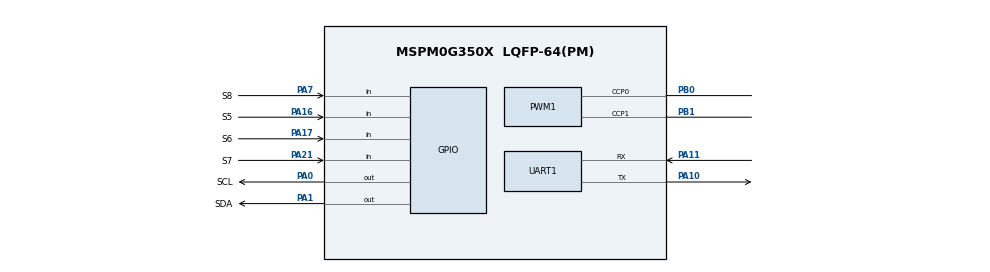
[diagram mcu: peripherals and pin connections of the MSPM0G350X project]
/**
 *
 * @cliArgs --device "MSPM0G350X" --part "Default" --package "LQFP-64(PM)" --product "mspm0_sdk@2.10.00.04"
 * @versions {"tool":"1.28.0+4712"}
 */

/**
 * Import the modules used in this configuration.
 */
const GPIO    = scripting.addModule("/ti/driverlib/GPIO", {}, false);
const GPIO1   = GPIO.addInstance();
const GPIO2   = GPIO.addInstance();
const GPIO3   = GPIO.addInstance();
const GPIO4   = GPIO.addInstance();
const GPIO5   = GPIO.addInstance();
const GPIO6   = GPIO.addInstance();
const GPIO7   = GPIO.addInstance();
const GPIO8   = GPIO.addInstance();
const GPIO9   = GPIO.addInstance();
const GPIO10  = GPIO.addInstance();
const PWM     = scripting.addModule("/ti/driverlib/PWM", {}, false);
const PWM1    = PWM.addInstance();
const SYSCTL  = scripting.addModule("/ti/driverlib/SYSCTL");
const SYSTICK = scripting.addModule("/ti/driverlib/SYSTICK");
const TIMER   = scripting.addModule("/ti/driverlib/TIMER", {}, false);
const TIMER1  = TIMER.addInstance();
const UART    = scripting.addModule("/ti/driverlib/UART", {}, false);
const UART1   = UART.addInstance();

/**
 * Write custom configuration values to the imported modules.
 */
const gate7  = system.clockTree["MFCLKGATE"];
gate7.enable = true;

GPIO1.port                               = "PORTB";
GPIO1.$name                              = "LED";
GPIO1.associatedPins[0].$name            = "PIN_0";
GPIO1.associatedPins[0].internalResistor = "PULL_DOWN";
GPIO1.associatedPins[0].assignedPin      = "22";

const Board = scripting.addModule("/ti/driverlib/Board", {}, false);

GPIO2.$name                              = "KEY";
GPIO2.port                               = "PORTB";
GPIO2.associatedPins[0].direction        = "INPUT";
GPIO2.associatedPins[0].internalResistor = "PULL_UP";
GPIO2.associatedPins[0].polarity         = "RISE";
GPIO2.associatedPins[0].$name            = "PIN_21";
GPIO2.associatedPins[0].assignedPin      = "21";

GPIO3.port                                = "PORTA";
GPIO3.$name                               = "ENCODERA";
GPIO3.associatedPins.create(2);
GPIO3.associatedPins[0].direction         = "INPUT";
GPIO3.associatedPins[0].interruptEn       = true;
GPIO3.associatedPins[0].polarity          = "RISE";
GPIO3.associatedPins[0].interruptPriority = "0";
GPIO3.associatedPins[0].$name             = "E1A";
GPIO3.associatedPins[0].assignedPin       = "8";
GPIO3.associatedPins[1].direction         = "INPUT";
GPIO3.associatedPins[1].interruptEn       = true;
GPIO3.associatedPins[1].polarity          = "RISE";
GPIO3.associatedPins[1].interruptPriority = "0";
GPIO3.associatedPins[1].$name             = "E1B";
GPIO3.associatedPins[1].assignedPin       = "9";

GPIO4.$name                         = "AIN1";
GPIO4.port                          = "PORTA";
GPIO4.associatedPins[0].$name       = "PIN_12";
GPIO4.associatedPins[0].assignedPin = "12";

GPIO5.$name                         = "AIN2";
GPIO5.port                          = "PORTA";
GPIO5.associatedPins[0].$name       = "PIN_13";
GPIO5.associatedPins[0].assignedPin = "13";

GPIO6.$name                         = "BIN1";
GPIO6.port                          = "PORTA";
GPIO6.associatedPins[0].$name       = "Pin_Bin1";
GPIO6.associatedPins[0].assignedPin = "14";

GPIO7.$name                         = "BIN2";
GPIO7.port                          = "PORTA";
GPIO7.associatedPins[0].$name       = "Pin_Bin2";
GPIO7.associatedPins[0].assignedPin = "15";

GPIO8.$name                               = "ENCODERB";
GPIO8.port                                = "PORTB";
GPIO8.associatedPins.create(2);
GPIO8.associatedPins[0].$name             = "E2A";
GPIO8.associatedPins[0].direction         = "INPUT";
GPIO8.associatedPins[0].interruptEn       = true;
GPIO8.associatedPins[0].polarity          = "RISE";
GPIO8.associatedPins[0].interruptPriority = "0";
GPIO8.associatedPins[0].assignedPin       = "14";
GPIO8.associatedPins[1].$name             = "E2B";
GPIO8.associatedPins[1].direction         = "INPUT";
GPIO8.associatedPins[1].interruptEn       = true;
GPIO8.associatedPins[1].polarity          = "RISE";
GPIO8.associatedPins[1].interruptPriority = "0";
GPIO8.associatedPins[1].assignedPin       = "15";

GPIO9.$name                         = "Gray";
GPIO9.port                          = "PORTA";
GPIO9.associatedPins.create(8);
GPIO9.associatedPins[0].$name       = "S1";
GPIO9.associatedPins[0].direction   = "INPUT";
GPIO9.associatedPins[0].assignedPin = "27";
GPIO9.associatedPins[1].$name       = "S2";
GPIO9.associatedPins[1].direction   = "INPUT";
GPIO9.associatedPins[1].assignedPin = "26";
GPIO9.associatedPins[2].$name       = "S3";
GPIO9.associatedPins[2].direction   = "INPUT";
GPIO9.associatedPins[2].assignedPin = "25";
GPIO9.associatedPins[3].$name       = "S4";
GPIO9.associatedPins[3].direction   = "INPUT";
GPIO9.associatedPins[3].assignedPin = "24";
GPIO9.associatedPins[4].$name       = "S5";
GPIO9.associatedPins[4].direction   = "INPUT";
GPIO9.associatedPins[4].assignedPin = "16";
GPIO9.associatedPins[4].pin.$assign = "PA16";
GPIO9.associatedPins[5].$name       = "S6";
GPIO9.associatedPins[5].direction   = "INPUT";
GPIO9.associatedPins[5].assignedPin = "17";
GPIO9.associatedPins[5].pin.$assign = "PA17";
GPIO9.associatedPins[6].$name       = "S7";
GPIO9.associatedPins[6].direction   = "INPUT";
GPIO9.associatedPins[6].assignedPin = "21";
GPIO9.associatedPins[6].pin.$assign = "PA21";
GPIO9.associatedPins[7].$name       = "S8";
GPIO9.associatedPins[7].direction   = "INPUT";
GPIO9.associatedPins[7].assignedPin = "7";
GPIO9.associatedPins[7].pin.$assign = "PA7";

GPIO10.$name                          = "OLED";
GPIO10.port                           = "PORTA";
GPIO10.associatedPins.create(2);
GPIO10.associatedPins[0].$name        = "SCL";
GPIO10.associatedPins[0].initialValue = "SET";
GPIO10.associatedPins[0].ioStructure  = "OD";
GPIO10.associatedPins[0].assignedPin  = "0";
GPIO10.associatedPins[0].pin.$assign  = "PA0";
GPIO10.associatedPins[1].$name        = "SDA";
GPIO10.associatedPins[1].initialValue = "SET";
GPIO10.associatedPins[1].ioStructure  = "OD";
GPIO10.associatedPins[1].assignedPin  = "1";
GPIO10.associatedPins[1].pin.$assign  = "PA1";

PWM1.$name                      = "PWM_0";
PWM1.timerStartTimer            = true;
PWM1.pwmMode                    = "EDGE_ALIGN_UP";
PWM1.timerCount                 = 3200;
PWM1.peripheral.$assign         = "TIMA1";
PWM1.peripheral.ccp0Pin.$assign = "PB0";
PWM1.peripheral.ccp1Pin.$assign = "PB1";
PWM1.PWM_CHANNEL_0.$name        = "ti_driverlib_pwm_PWMTimerCC0";
PWM1.PWM_CHANNEL_1.$name        = "ti_driverlib_pwm_PWMTimerCC1";
PWM1.ccp0PinConfig.$name        = "ti_driverlib_gpio_GPIOPinGeneric0";
PWM1.ccp1PinConfig.$name        = "ti_driverlib_gpio_GPIOPinGeneric1";

SYSCTL.forceDefaultClkConfig = true;
SYSCTL.clockTreeEn           = true;

SYSTICK.periodEnable      = true;
SYSTICK.systickEnable     = true;
SYSTICK.interruptPriority = "0";
SYSTICK.period            = 32;

TIMER1.timerClkDiv        = 8;
TIMER1.timerPeriod        = "5 ms";
TIMER1.timerStartTimer    = true;
TIMER1.timerMode          = "PERIODIC";
TIMER1.interrupts         = ["ZERO"];
TIMER1.$name              = "HEART";
TIMER1.timerClkPrescale   = 100;
TIMER1.peripheral.$assign = "TIMA0";

UART1.$name                    = "UART_0";
UART1.uartClkSrc               = "MFCLK";
UART1.enabledInterrupts        = ["RX"];
UART1.peripheral.$assign       = "UART0";
UART1.peripheral.rxPin.$assign = "PA11";
UART1.peripheral.txPin.$assign = "PA10";
UART1.txPinConfig.$name        = "ti_driverlib_gpio_GPIOPinGeneric2";
UART1.rxPinConfig.$name        = "ti_driverlib_gpio_GPIOPinGeneric3";

/**
 * Pinmux solution for unlocked pins/peripherals. This ensures that minor changes to the automatic solver in a future
 * version of the tool will not impact the pinmux you originally saw.  These lines can be completely deleted in order to
 * re-solve from scratch.
 */
GPIO1.associatedPins[0].pin.$suggestSolution = "PB22";
Board.peripheral.$suggestSolution            = "DEBUGSS";
Board.peripheral.swclkPin.$suggestSolution   = "PA20";
Board.peripheral.swdioPin.$suggestSolution   = "PA19";
GPIO2.associatedPins[0].pin.$suggestSolution = "PB21";
GPIO3.associatedPins[0].pin.$suggestSolution = "PA8";
GPIO3.associatedPins[1].pin.$suggestSolution = "PA9";
GPIO4.associatedPins[0].pin.$suggestSolution = "PA12";
GPIO5.associatedPins[0].pin.$suggestSolution = "PA13";
GPIO6.associatedPins[0].pin.$suggestSolution = "PA14";
GPIO7.associatedPins[0].pin.$suggestSolution = "PA15";
GPIO8.associatedPins[0].pin.$suggestSolution = "PB14";
GPIO8.associatedPins[1].pin.$suggestSolution = "PB15";
GPIO9.associatedPins[0].pin.$suggestSolution = "PA27";
GPIO9.associatedPins[1].pin.$suggestSolution = "PA26";
GPIO9.associatedPins[2].pin.$suggestSolution = "PA25";
GPIO9.associatedPins[3].pin.$suggestSolution = "PA24";
